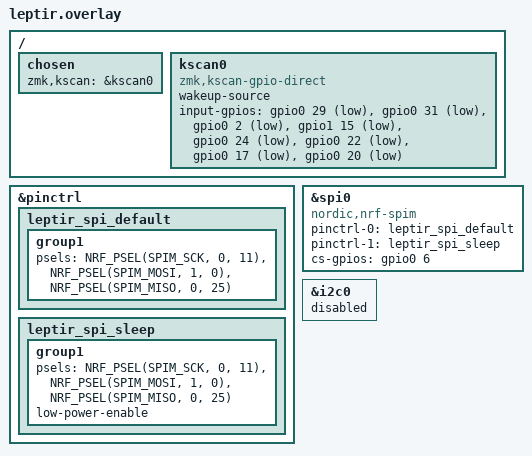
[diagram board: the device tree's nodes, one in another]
/*
 * boards/shields/leptir/leptir.overlay
 * Hardware description of the Leptir PCB: which nice!nano pin each part uses.
 * Pin mapping taken from leptir.kicad_sch / leptir.kicad_pcb (Phase 1).
 */

/ {
    /* Tell ZMK which key scanner to use. */
    chosen {
        zmk,kscan = &kscan0;
    };

    /*
     * Eight keys, each wired straight from one pin to ground (no matrix, no diodes).
     * ACTIVE_LOW + PULL_UP: the pin idles high and reads "pressed" when the
     * switch connects it to ground.
     * The ORDER here defines the key positions 0-7 used in the keymap.
     */
    kscan0: kscan0 {
        compatible = "zmk,kscan-gpio-direct";
        wakeup-source; /* a key press wakes the keyboard from deep sleep */
        input-gpios
            = <&gpio0 29 (GPIO_ACTIVE_LOW | GPIO_PULL_UP)> /* position 0 = SW1 (P0.29) */
            , <&gpio0 31 (GPIO_ACTIVE_LOW | GPIO_PULL_UP)> /* position 1 = SW2 (P0.31) */
            , <&gpio0  2 (GPIO_ACTIVE_LOW | GPIO_PULL_UP)> /* position 2 = SW3 (P0.02) */
            , <&gpio1 15 (GPIO_ACTIVE_LOW | GPIO_PULL_UP)> /* position 3 = SW4 (P1.15) */
            , <&gpio0 24 (GPIO_ACTIVE_LOW | GPIO_PULL_UP)> /* position 4 = SW5 (P0.24) */
            , <&gpio0 22 (GPIO_ACTIVE_LOW | GPIO_PULL_UP)> /* position 5 = SW6 (P0.22) */
            , <&gpio0 17 (GPIO_ACTIVE_LOW | GPIO_PULL_UP)> /* position 6 = SW7 (P0.17) */
            , <&gpio0 20 (GPIO_ACTIVE_LOW | GPIO_PULL_UP)> /* position 7 = SW8 (P0.20) */
            ;
    };
};

/*
 * Display wiring. ZMK's stock nice!view pins (MOSI P0.17, SCK P0.20) are SW7 and
 * SW8 on this PCB, so the display gets its own pin assignment:
 *   SCK  = P0.11, MOSI = P1.00, CS = P0.06.
 * MISO is never used by the display; P0.25 is not connected to anything.
 */
&pinctrl {
    leptir_spi_default: leptir_spi_default {
        group1 {
            psels = <NRF_PSEL(SPIM_SCK, 0, 11)>,
                    <NRF_PSEL(SPIM_MOSI, 1, 0)>,
                    <NRF_PSEL(SPIM_MISO, 0, 25)>;
        };
    };

    leptir_spi_sleep: leptir_spi_sleep {
        group1 {
            psels = <NRF_PSEL(SPIM_SCK, 0, 11)>,
                    <NRF_PSEL(SPIM_MOSI, 1, 0)>,
                    <NRF_PSEL(SPIM_MISO, 0, 25)>;
            low-power-enable;
        };
    };
};

/* The "nice_view" shield looks for an SPI bus with exactly this label. */
nice_view_spi: &spi0 {
    compatible = "nordic,nrf-spim";
    pinctrl-0 = <&leptir_spi_default>;
    pinctrl-1 = <&leptir_spi_sleep>;
    pinctrl-names = "default", "sleep";
    cs-gpios = <&gpio0 6 GPIO_ACTIVE_HIGH>;
};

/* I2C shares hardware with this SPI bus and would claim P0.17/P0.20. Keep it off. */
&i2c0 {
    status = "disabled";
};
